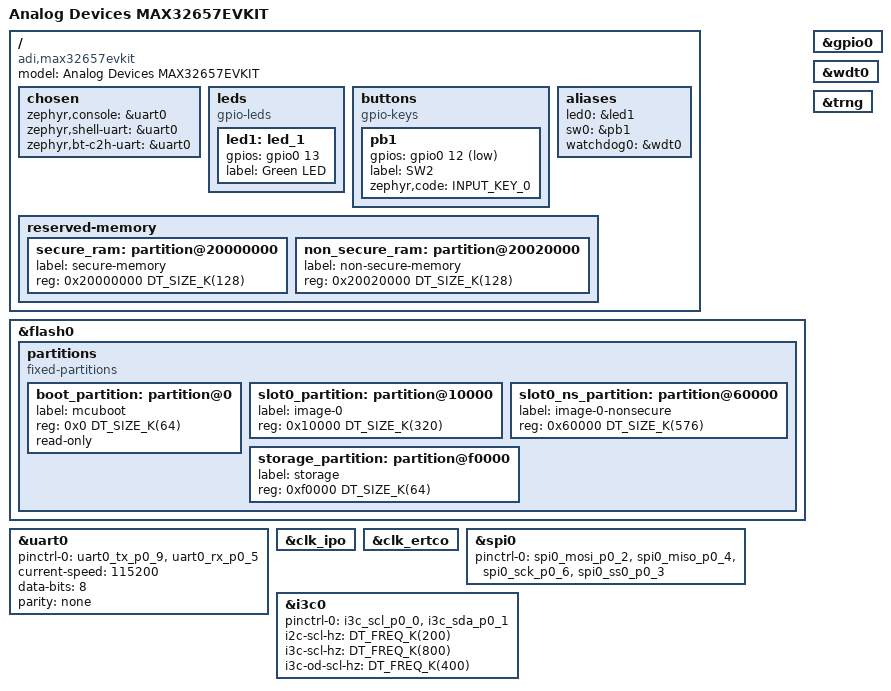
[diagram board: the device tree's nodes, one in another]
/*
 * Copyright (c) 2024 Analog Devices, Inc.
 *
 * SPDX-License-Identifier: Apache-2.0
 */

#include <adi/max32/max32657-pinctrl.dtsi>
#include <zephyr/dt-bindings/gpio/gpio.h>
#include <zephyr/dt-bindings/gpio/adi-max32-gpio.h>
#include <zephyr/dt-bindings/input/input-event-codes.h>

/ {
	model = "Analog Devices MAX32657EVKIT";
	compatible = "adi,max32657evkit";

	chosen {
		zephyr,console = &uart0;
		zephyr,shell-uart = &uart0;
		zephyr,bt-c2h-uart = &uart0;
	};

	leds {
		compatible = "gpio-leds";
		led1: led_1 {
			gpios = <&gpio0 13 GPIO_ACTIVE_HIGH>;
			label = "Green LED";
		};
	};

	buttons {
		compatible = "gpio-keys";
		pb1: pb1 {
			gpios = <&gpio0 12 (GPIO_PULL_UP | GPIO_ACTIVE_LOW)>;
			label = "SW2";
			zephyr,code = <INPUT_KEY_0>;
		};
	};

	/* These aliases are provided for compatibility with samples */
	aliases {
		led0 = &led1;
		sw0 = &pb1;
		watchdog0 = &wdt0;
	};

	reserved-memory {
		#address-cells = <1>;
		#size-cells = <1>;
		ranges;

		/* RAM split used by TFM */
		secure_ram: partition@20000000 {
			label = "secure-memory";
			reg = <0x20000000 DT_SIZE_K(128)>;
		};

		non_secure_ram: partition@20020000 {
			label = "non-secure-memory";
			reg = <0x20020000 DT_SIZE_K(128)>;
		};
	};
};

&flash0 {
	partitions {
		compatible = "fixed-partitions";
		#address-cells = <1>;
		#size-cells = <1>;

		boot_partition: partition@0 {
			label = "mcuboot";
			reg = <0x0 DT_SIZE_K(64)>;
			read-only;
		};
		slot0_partition: partition@10000 {
			label = "image-0";
			reg = <0x10000 DT_SIZE_K(320)>;
		};
		slot0_ns_partition: partition@60000 {
			label = "image-0-nonsecure";
			reg = <0x60000 DT_SIZE_K(576)>;
		};
		/*
		 * slot1_partition: partition@f0000 {
		 *  label = "image-1";
		 *	reg = <0xf0000 DT_SIZE_K(0)>;
		 * };
		 * slot1_ns_partition: partition@f0000 {
		 *	label = "image-1-nonsecure";
		 *	reg = <0xf0000 DT_SIZE_K(0)>;
		 * };
		 */
		storage_partition: partition@f0000 {
			label = "storage";
			reg = <0xf0000 DT_SIZE_K(64)>;
		};
	};
};

&uart0 {
	pinctrl-0 = <&uart0_tx_p0_9 &uart0_rx_p0_5>;
	pinctrl-names = "default";
	current-speed = <115200>;
	data-bits = <8>;
	parity = "none";
	status = "okay";
};

&clk_ipo {
	status = "okay";
};

/*
 * ERTCO requires for RTC
 */
&clk_ertco {
	status = "okay";
};

&gpio0 {
	status = "okay";
};

&wdt0 {
	status = "okay";
};

&trng {
	status = "okay";
};

&spi0 {
	status = "okay";
	pinctrl-0 = <&spi0_mosi_p0_2 &spi0_miso_p0_4 &spi0_sck_p0_6 &spi0_ss0_p0_3>;
	pinctrl-names = "default";
};

&i3c0 {
	status = "okay";
	pinctrl-0  = <&i3c_scl_p0_0 &i3c_sda_p0_1>;
	pinctrl-names = "default";
	i2c-scl-hz = <DT_FREQ_K(200)>;
	i3c-scl-hz = <DT_FREQ_K(800)>;
	i3c-od-scl-hz = <DT_FREQ_K(400)>;
};
